AUTOSAR XML (schema 00050)
package /ARRoot
  sender receiver interface application_sr_interface
    data detection_data
  sender receiver interface blobanalysis_sr_interface
    data frame_data
  swc implementation camera_input: programming-language=C, behavior=capture_data
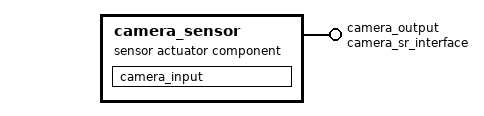
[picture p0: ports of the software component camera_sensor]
  sensor actuator sw component type camera_sensor
    provide port camera_output: provided-interface=camera_sr_interface
    behavior capture_data
      runnable camera_input: variable-access=accessed-variable=camera_data
  sender receiver interface camera_sr_interface
    data camera_data
  client server interface detection_templates_interface
    operation frame_compare
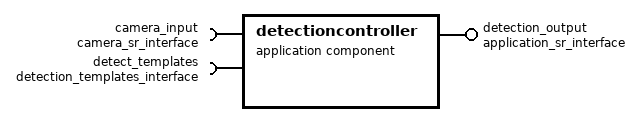
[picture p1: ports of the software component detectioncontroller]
  application sw component type detectioncontroller
    provide/require port blob_analysis: provided-required-interface=blobanalysis_sr_interface
    require port camera_input: required-interface=camera_sr_interface
    require port detect_templates: required-interface=detection_templates_interface
    provide port detection_output: provided-interface=application_sr_interface
    behavior detection
      4 x runnable:
        blobanalysis_data: variable-access=accessed-variable=frame_data
        camera_input: variable-access
        detection_output: variable-access=accessed-variable=detection_data
        detection_template_compare: synchronous-server-call-point=detect_templates.frame_compare
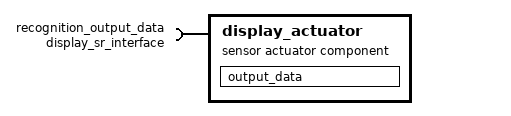
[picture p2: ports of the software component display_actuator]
  sensor actuator sw component type display_actuator
    require port recognition_output_data: required-interface=display_sr_interface
    behavior display_data
      runnable output_data: variable-access=accessed-variable=display_data
  swc implementation display_output: programming-language=C, behavior=display_data
  sender receiver interface display_sr_interface
    data display_data
  client server interface recognition_templates_interface
    operation frame_compare
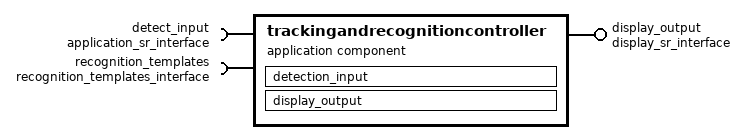
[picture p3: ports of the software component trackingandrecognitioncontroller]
  application sw component type trackingandrecognitioncontroller
    require port detect_input: required-interface=application_sr_interface
    provide port display_output: provided-interface=display_sr_interface
    require port recognition_templates: required-interface=recognition_templates_interface
    behavior recognition
      runnables runnable-entity=synchronous-server-call-point=recognition_templates.frame_compare:
        runnable detection_input: variable-access=accessed-variable=detection_data
        runnable display_output: variable-access=accessed-variable=display_data
